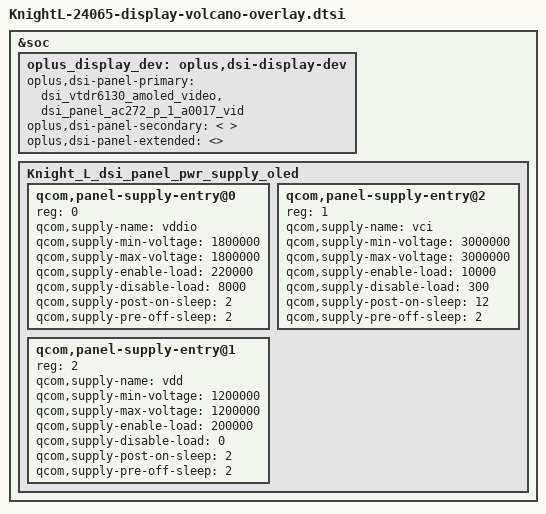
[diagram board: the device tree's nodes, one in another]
#include "panel/dsi-panel-AC272-P-1-A0017-dsc-vid.dtsi"

&soc {
	oplus_display_dev: oplus,dsi-display-dev {
		oplus,dsi-panel-primary = <
			&dsi_vtdr6130_amoled_video
			&dsi_panel_ac272_p_1_a0017_vid
		>;
		oplus,dsi-panel-secondary = <
		>;
		oplus,dsi-panel-extended = <>;
	};


	Knight_L_dsi_panel_pwr_supply_oled: Knight_L_dsi_panel_pwr_supply_oled {
		#address-cells = <1>;
		#size-cells = <0>;

		qcom,panel-supply-entry@0 {
			reg = <0>;
			qcom,supply-name = "vddio";
			qcom,supply-min-voltage = <1800000>;
			qcom,supply-max-voltage = <1800000>;
			qcom,supply-enable-load = <220000>;
			qcom,supply-disable-load = <8000>;
			qcom,supply-post-on-sleep = <2>;
			qcom,supply-pre-off-sleep = <2>;
		};

		qcom,panel-supply-entry@2 {
			reg = <1>;
			qcom,supply-name = "vci";
			qcom,supply-min-voltage = <3000000>;
			qcom,supply-max-voltage = <3000000>;
			qcom,supply-enable-load = <10000>;
			qcom,supply-disable-load = <300>;
			qcom,supply-post-on-sleep = <12>;
			qcom,supply-pre-off-sleep = <2>;
		};

		qcom,panel-supply-entry@1 {
			reg = <2>;
			qcom,supply-name = "vdd";
			qcom,supply-min-voltage = <1200000>;
			qcom,supply-max-voltage = <1200000>;
			qcom,supply-enable-load = <200000>;
			qcom,supply-disable-load = <0>;
			qcom,supply-post-on-sleep = <2>;
			qcom,supply-pre-off-sleep = <2>;
		};
	};
};
